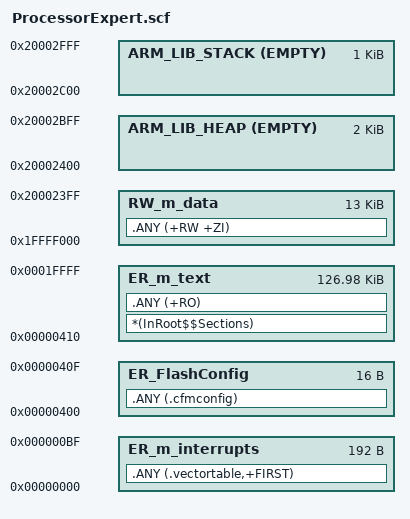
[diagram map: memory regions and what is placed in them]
#! armcc -E
; ###################################################################
;##
;##     THIS COMPONENT MODULE IS GENERATED BY THE TOOL. DO NOT MODIFY IT.
;##                                                
;##     Filename  : ProcessorExpert.scf                
;##                                                
;##     Project   : ProcessorExpert                   
;##                                                
;##     Processor : MKL25Z128VLK4                    
;##                                                
;##     Compiler  : Keil ARM C/C++ Compiler                    
;##                                                
;##     Date/Time : 2014-05-13, 15:56, # CodeGen: 9                     
;##                                                
;##     Abstract  :                                
;##                                                
;##     This file is used by the linker. It describes files to be linked,
;##     memory ranges, stack size, etc. For detailed description about linker
;##     command files see compiler documentation. This file is generated by default.
;##     You can switch off generation by setting the property "Generate linker file = no"
;##     in the "Build options" tab of the CPU component and then modify this file as needed.
;##
;##                                                
;## ###################################################################


#define m_interrupts_start              0x00000000
#define m_interrupts_size               0x000000C0

#define m_text_start                    0x00000410
#define m_text_size                     0x0001FBF0

#define m_data_start                    0x1FFFF000
#define m_data_size                     0x00004000

#define FlashConfig_start               0x00000400
#define FlashConfig_size                0x00000010

/*-Sizes-*/
#define stack_size                      0x0400
#define heap_size                       0x0800

LR_m_text m_text_start m_text_size  {  ; load region size_region
  ER_m_text m_text_start m_text_size  { ; load address = execution address
   *(InRoot$$Sections)
   .ANY (+RO)
  }
  RW_m_data m_data_start m_data_size-stack_size-heap_size  { ; RW data
   .ANY (+RW +ZI)
  }
  ARM_LIB_STACK m_data_start+m_data_size EMPTY -stack_size { ; Stack region growing down
  }
  ARM_LIB_HEAP m_data_start+m_data_size-stack_size-heap_size EMPTY heap_size { ; Heap region growing up
  }
}

LR_m_interrupts m_interrupts_start m_interrupts_size  {
  ER_m_interrupts m_interrupts_start m_interrupts_size  { ; load address = execution address
   .ANY (.vectortable,+FIRST)
  }
}
LR_FlashConfig FlashConfig_start FlashConfig_size  {
  ER_FlashConfig FlashConfig_start FlashConfig_size  { ; load address = execution address
   .ANY (.cfmconfig)
  }
}


